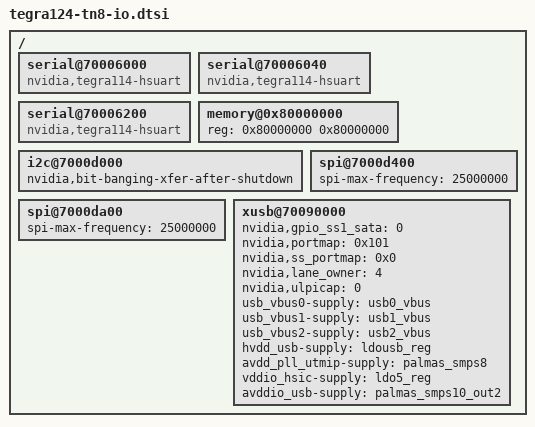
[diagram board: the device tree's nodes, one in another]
/ {
	serial@70006000 {
		compatible = "nvidia,tegra114-hsuart";
		status = "okay";
	};

	serial@70006040 {
		compatible = "nvidia,tegra114-hsuart";
		status = "okay";
	};

	serial@70006200 {
		compatible = "nvidia,tegra114-hsuart";
		status = "okay";
	};

	memory@0x80000000 {
		device_type = "memory";
		reg = <0x80000000 0x80000000>;
	};

	i2c@7000d000 {
		nvidia,bit-banging-xfer-after-shutdown;
	};

	spi@7000d400 {
		status = "okay";
		spi-max-frequency = <25000000>;
	};

	spi@7000da00 {
		status = "okay";
		spi-max-frequency = <25000000>;
	};

	xusb@70090000 {
		/* nvidia,uses_external_pmic;
		nvidia,gpio_controls_muxed_ss_lanes; */
		nvidia,gpio_ss1_sata = <0>;
		nvidia,portmap = <0x101>; /* SSP0, USB2P0 */
		nvidia,ss_portmap = <0x0>; /* SSP0 on USB2P0 */
		nvidia,lane_owner = <4>; /* USB3P0 */
		nvidia,ulpicap = <0>; /* No ulpi support. can we remove */
		usb_vbus0-supply = <&usb0_vbus>;
		usb_vbus1-supply = <&usb1_vbus>;
		usb_vbus2-supply = <&usb2_vbus>;
		hvdd_usb-supply = <&ldousb_reg>;
		avdd_pll_utmip-supply = <&palmas_smps8>;
		vddio_hsic-supply = <&ldo5_reg>;
		avddio_usb-supply = <&palmas_smps10_out2>;
		status = "okay";
	};
};
